# RE01_256KB register map
Vendor: Renesas Electronics Corporation; Series: RE01; File version: 1.00.01
CPU: CM0PLUS r0p1, little endian, MPU, no FPU, VTOR, 2 interrupt priority bits, 32 interrupts
Registers are 8-bit, read-write, reset 0x0 unless marked. A register's access mark holds for its fields unless they carry their own. Offsets are from the block's base; [hi:lo] are bit positions; {n}, {i} and the like mark numbered series.

## SPI0 — Serial Peripheral Interface 0
Base 0x40072000
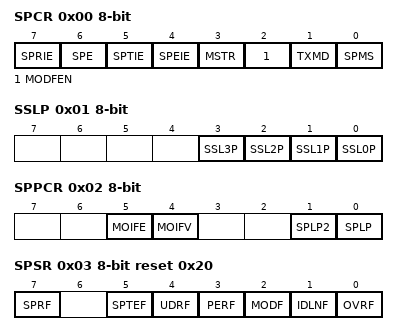
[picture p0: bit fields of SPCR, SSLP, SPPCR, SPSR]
0x00 SPCR — SPI Control Register
  [7] SPRIE — SPI Receive Buffer Full Interrupt Enable
    0=Disable SPI receive buffer full interrupt requests; 1=Enable SPI receive buffer full interrupt requests
  [6] SPE — SPI Function Enable
    0=Disable SPI function; 1=Enable SPI function
  [5] SPTIE — Transmit Buffer Empty Interrupt Enable
    0=Disable transmit buffer empty interrupt requests; 1=Enable transmit buffer empty interrupt requests
  [4] SPEIE — SPI Error Interrupt Enable
    0=Disable SPI error interrupt requests; 1=Enable SPI error interrupt requests
  [3] MSTR — SPI Master/Slave Mode Select
    0=Select slave mode; 1=Select master mode
  [2] MODFEN — Mode Fault Error Detection Enable
    0=Disable detection of mode fault errors; 1=Enable detection of mode fault errors
  [1] TXMD — Communications Operating Mode Select
    0=Select full-duplex synchronous serial communications; 1=Select serial communications with transmit-only
  [0] SPMS — SPI Mode Select
    0=Select SPI operation (4-wire method); 1=Select clock synchronous operation (3-wire method)
0x01 SSLP — SPI Slave Select Polarity Register
  [n] SSL{n}P (n=0..3) — SSLn{n} Signal Polarity Setting
    0=Set SSLn{n} signal to active-low; 1=Set SSLn{n} signal to active-high
0x02 SPPCR — SPI Pin Control Register
  [5] MOIFE — MOSI Idle Value Fixing Enable
    0=Set MOSI output value to equal final data from previous transfer; 1=Set MOSI output value to equal value set in the MOIFV bit
  [4] MOIFV — MOSI Idle Fixed Value
    0=Set level output on MOSIn pin during MOSI idling to low; 1=Set level output on MOSIn pin during MOSI idling to high
  [1] SPLP2 — SPI Loopback 2
    0=Normal mode; 1=Loopback mode (receive data = transmit data)
  [0] SPLP — SPI Loopback
    0=Normal mode; 1=Loopback mode (receive data = inverted transmit data)
0x03 SPSR reset 0x20 — SPI Status Register
  [7] SPRF — SPI Receive Buffer Full Flag
    0=No valid data is in SPDR/SPDR_HA; 1=Valid data is in SPDR/SPDR_HA
  [5] SPTEF — SPI Transmit Buffer Empty Flag
    0=Data is in the transmit buffer; 1=No data is in the transmit buffer
  [4] UDRF — Underrun Error Flag
    0=Mode fault error occurred (MODF = 1); 1=Underrun error occurred (MODF = 1)
  [3] PERF — Parity Error Flag
    0=No parity error occurred; 1=Parity error occurred
  [2] MODF — Mode Fault Error Flag
    0=No mode fault or underrun error occurred; 1=Mode fault error or underrun error occurred
  [1] IDLNF ro — SPI Idle Flag
    0=SPI is in the idle state; 1=SPI is in the transfer state
  [0] OVRF — Overrun Error Flag
    0=No overrun error occurred; 1=Overrun error occurred
0x04 SPDR 32-bit — SPI Data Register
0x04 SPDR_HA 16-bit (alternate view of SPDR) — SPI Data Register
0x04 SPDR_BY (alternate view of SPDR) — SPI Data Register
0x08 SPSCR — SPI Sequence Control Register
  [2:0] SPSLN — SPI Sequence Length Specification
    0=Sequence Length is 1 (Referenced SPCMDn, n = 0→0→…); 1=Sequence Length is 2 (Referenced SPCMDn, n = 0→1→0→…); 2=Sequence Length is 3 (Referenced SPCMDn, n = 0→1→2→0→…); 3=Sequence Length is 4 (Referenced SPCMDn, n = 0→1→2→3→0→…); 4=Sequence Length is 5 (Referenced SPCMDn, n = 0→1→2→3→4→0→…); 5=Sequence Length is 6 (Referenced SPCMDn, n = 0→1→2→3→4→5→0→…); 6=Sequence Length is 7 (Referenced SPCMDn, n = 0→1→2→3→4→5→6→0→…); 7=Sequence Length is 8 (Referenced SPCMDn, n = 0→1→2→3→4→5→6→7→0→…)
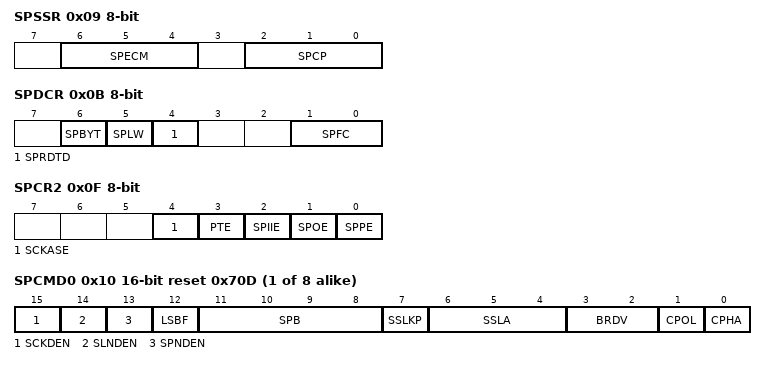
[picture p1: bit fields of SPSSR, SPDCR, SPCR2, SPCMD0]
0x09 SPSSR ro — SPI Sequence Status Register
  [6:4] SPECM — SPI Error Command
    {v}=SPCMD{v} (v=0..7)
  [2:0] SPCP — SPI Command Pointer
    {v}=SPCMD{v} (v=0..7)
0x0A SPBR reset 0xFF — SPI Bit Rate Register
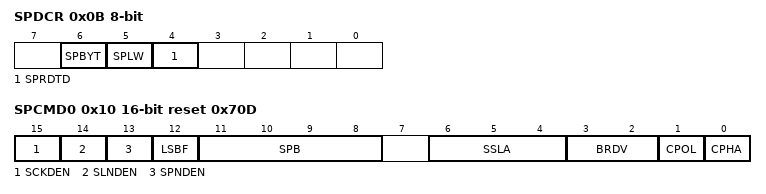
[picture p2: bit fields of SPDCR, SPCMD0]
0x0B SPDCR — SPI Data Control Register
  [6] SPBYT — SPI Byte Access Specification
    0=SPDR is accessed in halfword or word (SPLW is valid); 1=SPDR is accessed in byte (SPLW is invalid)
  [5] SPLW — SPI Word Access/Halfword Access Specification
    0=Set SPDR_HA to valid for halfword access; 1=Set SPDR to valid for word access
  [4] SPRDTD — SPI Receive/Transmit Data Select (only SPI0)
    0=Read SPDR/SPDR_HA values from receive buffer; 1=Read SPDR/SPDR_HA values from transmit buffer, but only if the transmit buffer is empty
  [1:0] SPFC — Number of Frames Specification (only SPI0)
    0=1 frame; 1=2 frames; 2=3 frames; 3=4 frames
0x0C SPCKD — SPI Clock Delay Register
  [2:0] SCKDL — RSPCK Delay Setting
    {v}={v+1} RSPCK (v=0..7)
0x0D SSLND — SPI Slave Select Negation Delay Register
  [2:0] SLNDL — SSL Negation Delay Setting
    {v}={v+1} RSPCK (v=0..7)
0x0E SPND — SPI Next-Access Delay Register
  [2:0] SPNDL — SPI Next-Access Delay Setting
    {v}={v+1} RSPCK + 2 PCLKA (v=0..7)
0x0F SPCR2 — SPI Control Register 2
  [4] SCKASE — RSPCK Auto-Stop Function Enable
    0=Disable RSPCK auto-stop function; 1=Enable RSPCK auto-stop function
  [3] PTE — Parity Self-Testing
    0=Disable self-diagnosis function of the parity circuit; 1=Enable self-diagnosis function of the parity circuit
  [2] SPIIE — SPI Idle Interrupt Enable
    0=Disable idle interrupt requests; 1=Enable idle interrupt requests
  [1] SPOE — Parity Mode
    0=Select even parity for transmission and reception; 1=Select odd parity for transmission and reception
  [0] SPPE — Parity Enable
    0=Do not add parity bit to transmit data and do not check parity bit of receive data; 1=When SPCR.TXMD = 0: Add parity bit to transmit data and check parity bit of receive data When SPCR.TXMD = 1: Add parity bit to transmit data but do not check parity bit of receive data
{0x10+2i} SPCMD{i} (i=0..7) 16-bit reset 0x70D — SPI Command Register {i}
  [15] SCKDEN — RSPCK Delay Setting Enable
    0=Select RSPCK delay of 1 RSPCK; 1=Select RSPCK delay equal to the setting in the SPI Clock Delay Register (SPCKD)
  [14] SLNDEN — SSL Negation Delay Setting Enable
    0=Select SSL negation delay of 1 RSPCK; 1=Select SSL negation delay equal to the setting in the SPI Slave Select Negation Delay Register (SSLND)
  [13] SPNDEN — SPI Next-Access Delay Enable
    0=Select next-access delay of 1 RSPCK + 2 PCLKB; 1=Select next-access delay equal to the setting in the SPI Next-Access Delay Register (SPND)
  [12] LSBF — SPI LSB First
    0=MSB-first; 1=LSB-first
  [11:8] SPB — SPI Data Length Setting
    0=20 bits; 1=24 bits; 2=32 bits; 3=32 bits; {v}={v+1} bits (v=8..15); other=Others (8 bits)
  [7] SSLKP — SSL Signal Level Keeping (only SPI0)
    0=Negate all SSL signals on completion of transfer; 1=Keep SSL signal level from the end of transfer until the beginning of the next access
  [6:4] SSLA — SSL Signal Assertion Setting
    {v}=SSL{v} (v=0..3); other=Others (Setting prohibited)
  [3:2] BRDV — Bit Rate Division Setting
    0=Base bit rate; 1=Base bit rate divided by 2; 2=Base bit rate divided by 4; 3=Base bit rate divided by 8
  [1] CPOL — RSPCK Polarity Setting
    0=Set RSPCK low during idle; 1=Set RSPCK high during idle
  [0] CPHA — RSPCK Phase Setting
    0=Select data sampling on leading edge, data change on trailing edge; 1=Select data change on leading edge, data sampling on trailing edge

## SPI1 — Serial Peripheral Interface 1
Base 0x40072100
Registers as SPI0, without SPSCR, SPSSR, SPCMD*; these are added or differ:
0x0B SPDCR — SPI Data Control Register
  [6] SPBYT — SPI Byte Access Specification
    0=SPDR is accessed in halfword or word (SPLW is valid); 1=SPDR is accessed in byte (SPLW is invalid)
  [5] SPLW — SPI Word Access/Halfword Access Specification
    0=Set SPDR_HA to valid for halfword access; 1=Set SPDR to valid for word access
  [4] SPRDTD — SPI Receive/Transmit Data Select (only SPI0)
    0=Read SPDR/SPDR_HA values from receive buffer; 1=Read SPDR/SPDR_HA values from transmit buffer, but only if the transmit buffer is empty
0x10 SPCMD0 16-bit reset 0x70D — SPI Command Register 0
  [15] SCKDEN — RSPCK Delay Setting Enable
    0=Select RSPCK delay of 1 RSPCK; 1=Select RSPCK delay equal to the setting in the SPI Clock Delay Register (SPCKD)
  [14] SLNDEN — SSL Negation Delay Setting Enable
    0=Select SSL negation delay of 1 RSPCK; 1=Select SSL negation delay equal to the setting in the SPI Slave Select Negation Delay Register (SSLND)
  [13] SPNDEN — SPI Next-Access Delay Enable
    0=Select next-access delay of 1 RSPCK + 2 PCLKB; 1=Select next-access delay equal to the setting in the SPI Next-Access Delay Register (SPND)
  [12] LSBF — SPI LSB First
    0=MSB-first; 1=LSB-first
  [11:8] SPB — SPI Data Length Setting
    0=20 bits; 1=24 bits; 2=32 bits; 3=32 bits; {v}={v+1} bits (v=8..15); other=Others (8 bits)
  [6:4] SSLA — SSL Signal Assertion Setting
    {v}=SSL{v} (v=0..3); other=Others (Setting prohibited)
  [3:2] BRDV — Bit Rate Division Setting
    0=Base bit rate; 1=Base bit rate divided by 2; 2=Base bit rate divided by 4; 3=Base bit rate divided by 8
  [1] CPOL — RSPCK Polarity Setting
    0=Set RSPCK low during idle; 1=Set RSPCK high during idle
  [0] CPHA — RSPCK Phase Setting
    0=Select data sampling on leading edge, data change on trailing edge; 1=Select data change on leading edge, data sampling on trailing edge
